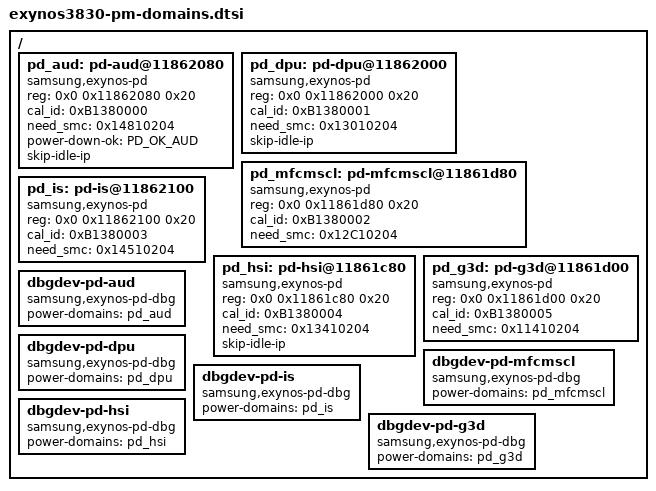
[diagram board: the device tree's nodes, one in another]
/*
 * SAMSUNG EXYNOS3830 SoC PM Domains device tree source
 *
 * Copyright (c) 2019 Samsung Electronics Co., Ltd.
 *		http://www.samsung.com
 *
 * SAMSUNG EXYNOS3830 SoC PM domains device nodes are listed in this file.
 * EXYNOS3830 based board files can include this file and provide
 * values for board specfic bindings.
 *
 * This program is free software; you can redistribute it and/or modify
 * it under the terms of the GNU General Public License version 2 as
 * published by the Free Software Foundation.
 */
#include <dt-bindings/power/exynos-power.h>

/ {
	pd_aud: pd-aud@11862080 {
		compatible = "samsung,exynos-pd";
		reg = <0x0 0x11862080 0x20>;
		cal_id = <0xB1380000>;
		need_smc = <0x14810204>;
		status = "okay";
		power-down-ok = <PD_OK_AUD>;
		#power-domain-cells = <0>;
		skip-idle-ip;
	};

	pd_dpu: pd-dpu@11862000 {
		compatible = "samsung,exynos-pd";
		reg = <0x0 0x11862000 0x20>;
		cal_id = <0xB1380001>;
		need_smc = <0x13010204>;
		status = "okay";
		#power-domain-cells = <0>;
		skip-idle-ip;
	};

	pd_mfcmscl: pd-mfcmscl@11861d80 {
		compatible = "samsung,exynos-pd";
		reg = <0x0 0x11861d80 0x20>;
		cal_id = <0xB1380002>;
		need_smc = <0x12C10204>;
		status = "okay";
		#power-domain-cells = <0>;
	};

	pd_is: pd-is@11862100 {
		compatible = "samsung,exynos-pd";
		reg = <0x0 0x11862100 0x20>;
		cal_id = <0xB1380003>;
		need_smc = <0x14510204>;
		status = "okay";
		#power-domain-cells = <0>;
	};

	pd_hsi: pd-hsi@11861c80 {
		compatible = "samsung,exynos-pd";
		reg = <0x0 0x11861c80 0x20>;
		cal_id = <0xB1380004>;
		need_smc = <0x13410204>;
		status = "okay";
		#power-domain-cells = <0>;
		skip-idle-ip;
	};

	pd_g3d: pd-g3d@11861d00 {
		compatible = "samsung,exynos-pd";
		reg = <0x0 0x11861d00 0x20>;
		cal_id = <0xB1380005>;
		need_smc = <0x11410204>;
		status = "okay";
		#power-domain-cells = <0>;
	};

	dbgdev-pd-aud {
		compatible = "samsung,exynos-pd-dbg";
		power-domains = <&pd_aud>;
	};

	dbgdev-pd-dpu {
		compatible = "samsung,exynos-pd-dbg";
		power-domains = <&pd_dpu>;
	};

	dbgdev-pd-mfcmscl {
		compatible = "samsung,exynos-pd-dbg";
		power-domains = <&pd_mfcmscl>;
	};

	dbgdev-pd-is {
		compatible = "samsung,exynos-pd-dbg";
		power-domains = <&pd_is>;
	};

	dbgdev-pd-hsi {
		compatible = "samsung,exynos-pd-dbg";
		power-domains = <&pd_hsi>;
	};

	dbgdev-pd-g3d {
		compatible = "samsung,exynos-pd-dbg";
		power-domains = <&pd_g3d>;
	};
};
